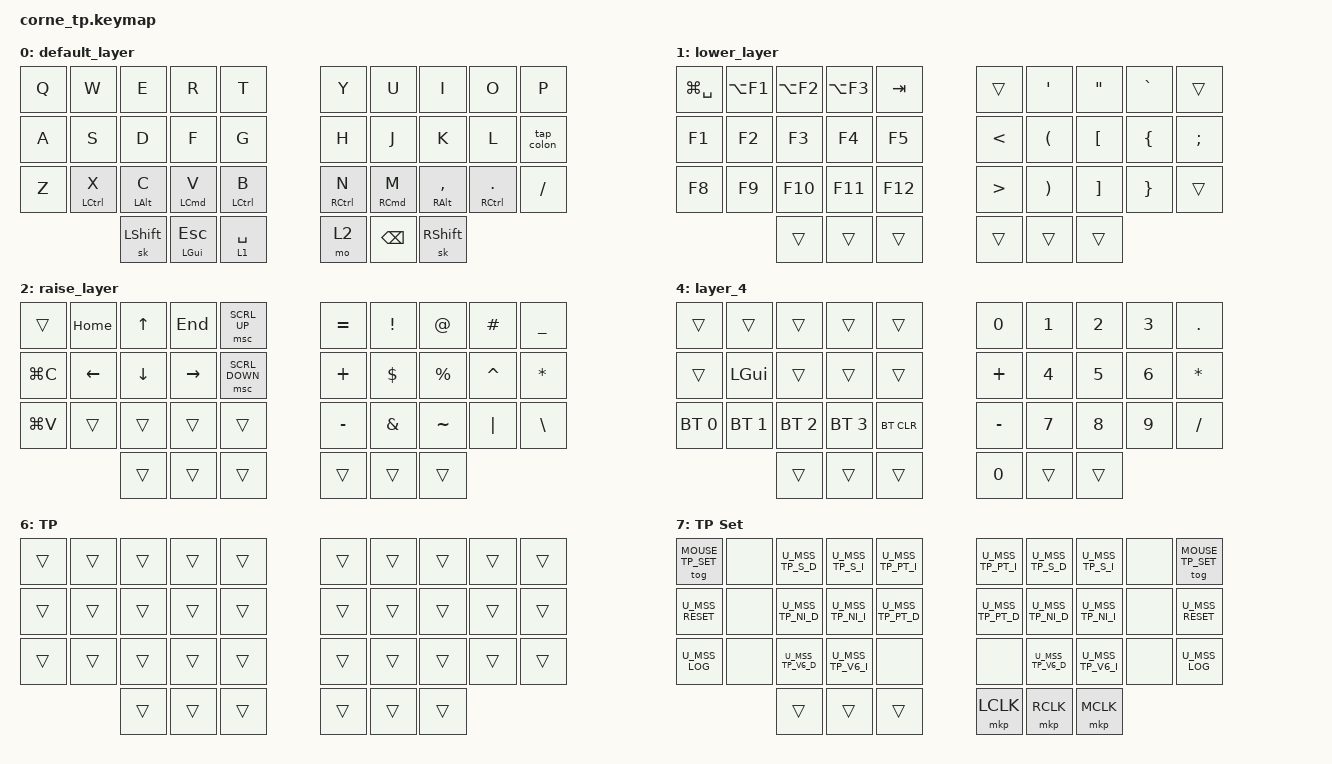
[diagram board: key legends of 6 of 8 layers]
/*
* Copyright (c) 2020 The ZMK Contributors
*
* SPDX-License-Identifier: MIT
*/

#include "zmk-helpers/helper.h"

#define ZMK_MOUSE_DEFAULT_SCRL_VAL 80

#define HM_TAPPING_TERM 300
#define HM_TAPPING_TERM_FAST 200
#define HM_PRIOR_IDLE 100

#include "zmk-helpers/key-labels/36.h"                                      // key-position labels
#include <behaviors.dtsi>
#include <dt-bindings/zmk/bt.h>
#include <dt-bindings/zmk/keys.h>

// BEGIN TRACKPOINT
#define BASE 0
#define LOWER 1
#define MOUSE_KEYS 5
#define MOUSE_TP 6
#define MOUSE_TP_SET 7

/*
 * Defines to enable/disable features
 *
 * These defines allow us to conditionally enable and disable parts of the keymap config.
 *
 * For example, if we decide to build the firmware without the mouse features, we can
 * disable all the config options that rely on those forks and modules without having
 * to edit the entire keymap file manually every time.
 */

#define HAS_MOUSE_KEYS
#define HAS_MOUSE_TP

#ifdef HAS_MOUSE_KEYS
  #include <dt-bindings/zmk/mouse.h>
  #include <behaviors/mouse_keys.dtsi>
#endif  // HAS_MOUSE_KEYS

#ifdef HAS_MOUSE_TP
  // We store the trackpoint settings in a separate file
  // to make organization a little easier.
  #include "include/mouse_tp.dtsi"
#endif  // HAS_MOUSE_TP



// Adjust layer keys based on enabled features.
//
// This prevents build errors when we build the firmware
// without the mouse keys PR or the TP module.
#ifdef HAS_MOUSE_KEYS
  #define U_THUMB_INNER &mo MOUSE_KEYS
#else
  #define U_THUMB_INNER &none
#endif  // HAS_MOUSE_KEYS

#ifdef HAS_MOUSE_TP
  #define U_TOG_TP_SET &tog MOUSE_TP_SET
#else
  #define U_TOG_TP_SET &none
#endif  // HAS_MOUSE_TP

// END TRACKPOINT

#define KEYS_L LT0 LT1 LT2 LT3 LT4 LM0 LM1 LM2 LM3 LM4 LB0 LB1 LB2 LB3 LB4  // left-hand keys
#define KEYS_R RT0 RT1 RT2 RT3 RT4 RM0 RM1 RM2 RM3 RM4 RB0 RB1 RB2 RB3 RB4  // right-hand keys
#define THUMBS LH2 LH1 LH0 RH0 RH1 RH2                                      // thumb keys

&lt {
    // Increase layer tap time

    tapping-term-ms = <200>;

    // Quickly tap-tap-holding the lt button will repeat the tap behavior
    // For example enter-enter-hold, will output multiple enter while you
    // keep holding the key.
    // But holding enter without double tapping, will activate the layer.

    quick-tap-ms = <150>;
    flavor = "tap-unless-interrupted";
};

/ {
    behaviors {
        // Positional Homerow mods
        // Homerow mods that prevent accidental activations when rolling keys,
        // such as when typing `st` or `ne` on colemak-dh layouts or `as` on
        // qwerty.
        //
        // Works by only allowing a mod to activate within tapping-term if
        // it's on the opposite side of the keyboard or on the same side thumb
        // keys.
        // Further optimization using urob's timerless homerow mods method:
        // https://github.com/urob/zmk-config#timeless-homerow-mods

        hml: homerow_mods_left {
            compatible = "zmk,behavior-hold-tap";
            #binding-cells = <2>;
            bindings = <&kp>, <&kp>;

            flavor = "balanced";
            tapping-term-ms = <HM_TAPPING_TERM>;
            quick-tap-ms = <175>;                // repeat on tap-into-hold
            require-prior-idle-ms = <HM_PRIOR_IDLE>;
            hold-trigger-key-positions = <KEYS_R THUMBS>;
            hold-trigger-on-release;
        };

        hmr: homerow_mods_right {
            compatible = "zmk,behavior-hold-tap";
            #binding-cells = <2>;
            bindings = <&kp>, <&kp>;

            flavor = "balanced";
            tapping-term-ms = <HM_TAPPING_TERM>;
            quick-tap-ms = <175>;
            require-prior-idle-ms = <HM_PRIOR_IDLE>;
            hold-trigger-key-positions = <KEYS_L THUMBS>;
            hold-trigger-on-release;
        };

        // Positional Homerow mods for shift
        // Use faster tapping term and disable some features that may
        // cause false negatives.

        //hmsl: hm_shift_l {
        //    compatible = "zmk,behavior-hold-tap";
        //    #binding-cells = <2>;
        //    bindings = <&kp>, <&kp>;

        //    flavor = "balanced";
        //    tapping-term-ms = <HM_TAPPING_TERM_FAST>;
        //    quick-tap-ms = <175>;
        //    require-prior-idle-ms = <HM_PRIOR_IDLE>;
        //    hold-trigger-key-positions = <KEYS_R THUMBS>;

        //    // hold-trigger-on-release;
        //};

        //hmsr: hm_shift_r {
        //    compatible = "zmk,behavior-hold-tap";
        //    #binding-cells = <2>;
        //    bindings = <&kp>, <&kp>;

        //    flavor = "balanced";
        //    tapping-term-ms = <HM_TAPPING_TERM_FAST>;
        //    quick-tap-ms = <175>;
        //    require-prior-idle-ms = <HM_PRIOR_IDLE>;
        //    hold-trigger-key-positions = <KEYS_L THUMBS>;

        //    // hold-trigger-on-release;
        //};

        /*
         * Non-Positional Homerow Mods
         * Used for &mm_grescm_gui behavior on left hand.
         *
         * Usage: &hm LSHFT T
         * Tap: T
         * Tap-Tap-Hold: Repeat T
         * Hold: LSHIFT
         */

        hm: homerow_mods {
            compatible = "zmk,behavior-hold-tap";
            #binding-cells = <2>;
            bindings = <&kp>, <&kp>;

            flavor = "balanced";
            tapping-term-ms = <HM_TAPPING_TERM>;
            quick-tap-ms = <200>;
        };

        rot_msc: sensor_rotate_msc {
            compatible = "zmk,behavior-sensor-rotate-var";
            #sensor-binding-cells = <2>;
            bindings = <&msc>, <&msc>;
            tap-ms = <20>;

        };

        rot_kp: sensor_rotate_kp {
            compatible = "zmk,behavior-sensor-rotate-var";
            #sensor-binding-cells = <2>;
            bindings = <&kp>, <&kp>;
        };
    };
};

/ {
    macros {
        //moom_full: moom_full {
        //    compatible = "zmk,behavior-macro";
        //    #binding-cells = <0>;
        //    bindings = <&kp LC(LA(LG(SPACE))) &kp SPACE>;
        //    label = "MOOM_FULL";
        //};

        //moom_left: moom_left {
        //    compatible = "zmk,behavior-macro";
        //    #binding-cells = <0>;
        //    bindings = <&kp LA(LC(LG(SPACE))) &kp LG(LEFT)>;
        //    label = "MOOM_LEFT";
        //};

        //moom_right: moom_right {
        //    compatible = "zmk,behavior-macro";
        //    #binding-cells = <0>;
        //    bindings = <&kp LA(LC(LG(SPACE))) &kp LG(RIGHT_ARROW)>;
        //    label = "MOOM_RIGHT";
        //};

        save_vim: save_vim {
            compatible = "zmk,behavior-macro";
            #binding-cells = <0>;
            bindings = <&kp ESCAPE &kp ESCAPE &kp SPACE &kp SPACE>;
            label = "SAVE_VIM";
        };

        tap_colon: super_colon {
            compatible = "zmk,behavior-macro";
            #binding-cells = <0>;
            bindings = <&kp COLON>;
            label = "SUPER_COLON";
        };
    };

    combos {
        compatible = "zmk,combos";
        timeout-ms = <30>;

        numlayer {
            bindings = <&sl 4>;
            key-positions = <LM1 LM2>;
        };

        homerow_hyperspace {
            bindings = <&kp LS(LA(LC(LG(SPACE))))>;
            key-positions = <LH1 RH1>;
        };

        //cmd_space {
        //    bindings = <&kp LG(SPACE)>;
        //    key-positions = <LM0 RM0>;
        //};

        return {
            bindings = <&kp RETURN>;
            key-positions = <RM2 RM3>;
        };

        hyper {
            bindings = <&sk LA(LC(LG(LEFT_SHIFT)))>;
            key-positions = <LH2 RH2>;
        };

        left_click {
            bindings = <&mkp LCLK>;
            key-positions = <RH0 RH1>;
        };

        middle_click {
            bindings = <&mkp MCLK>;
            key-positions = <RH1 RB0>;
        };

        right_click {
            bindings = <&mkp RCLK>;
            key-positions = <RH1 RH2>;
        };

        control_b {
          bindings = <&kp LC(B)>;
          key-positions = <LM4 RM4>;
        };

        //less_than {
        //  bindings = <&kp LESS_THAN>;
        //  key-positions = <LT1 LT2 LT3>;
        //};

        //greater_than {
        //  bindings = <&kp GREATER_THAN>;
        //  key-positions = <RT1 RT2 RT3>;
        //};

        caps_word_combo {
          bindings = <&caps_word>;
          key-positions = <LB3 LB2>;
        };
    };

    behaviors {
        //thumb_0: thumb_0 {
        //    compatible = "zmk,behavior-tap-dance";
        //    label = "THUMB_0";
        //    #binding-cells = <0>;
        //    bindings = <&sk LEFT_SHIFT>, <&caps_word>;
        //};

        //thumb_1: thumb_1 {
        //    compatible = "zmk,behavior-tap-dance";
        //    label = "THUMB_1";
        //    #binding-cells = <0>;
        //    bindings = <&sk RIGHT_SHIFT>, <&caps_word>;
        //};

        //paren: paren {
        //    compatible = "zmk,behavior-hold-tap";
        //    label = "PAREN";
        //    bindings = <&kp>, <&kp>;

        //    #binding-cells = <2>;
        //    tapping-term-ms = <150>;
        //    flavor = "tap-preferred";
        //};

        //alpha_ht: alpha_ht {
        //    compatible = "zmk,behavior-hold-tap";
        //    label = "ALPHA_HT";
        //    bindings = <&kp>, <&kp>;

        //    #binding-cells = <2>;
        //    tapping-term-ms = <150>;
        //    flavor = "tap-preferred";
        //};
    };

    keymap {
        compatible = "zmk,keymap";

        default_layer {
            bindings = <
&kp Q  &kp W                &kp E            &kp R                 &kp T                  &kp Y                 &kp U                 &kp I                 &kp O                   &kp P
&kp A  &kp S                &kp D            &kp F                 &kp G                  &kp H                 &kp J                 &kp K                 &kp L                   &tap_colon
&kp Z  &hml LEFT_CONTROL X  &hml LEFT_ALT C  &hml LEFT_COMMAND V   &hml LEFT_CONTROL B    &hmr RIGHT_CONTROL N  &hmr RIGHT_COMMAND M  &hmr RIGHT_ALT COMMA  &hmr RIGHT_CONTROL DOT  &kp SLASH 
                      &sk LEFT_SHIFT         &hmr LEFT_GUI ESCAPE  &lt 1 SPACE            &mo 2                 &kp BACKSPACE         &sk RIGHT_SHIFT
            >;
            sensor-bindings = <&rot_msc SCRL_UP SCRL_DOWN &inc_dec_kp LEFT RIGHT>;
        };

        lower_layer {
            bindings = <
&kp LG(SPACE)  &kp LA(F1)  &kp LA(F2)  &kp LA(F3)  &kp TAB                  &trans             &kp SINGLE_QUOTE       &kp DOUBLE_QUOTES   &kp GRAVE       &trans
&kp F1         &kp F2      &kp F3      &kp F4      &kp F5                   &kp LESS_THAN      &kp LEFT_PARENTHESIS   &kp LEFT_BRACKET   &kp LEFT_BRACE   &kp SEMICOLON
&kp F8         &kp F9      &kp F10     &kp F11     &kp F12                  &kp GREATER_THAN   &kp RIGHT_PARENTHESIS  &kp RIGHT_BRACKET  &kp RIGHT_BRACE  &trans
                           &trans      &trans      &trans                   &trans             &trans                 &trans
            >;
        };

        raise_layer {
            bindings = <
&trans      &kp HOME  &kp UP                 &kp END    &msc SCRL_UP       &kp EQUAL  &kp EXCL       &kp AT       &kp HASH   &kp UNDER
&kp LG(C)   &kp LEFT  &kp DOWN               &kp RIGHT  &msc SCRL_DOWN     &kp PLUS   &kp DOLLAR     &kp PERCENT  &kp CARET  &kp STAR
&kp LG(V)   &trans    &trans                 &trans     &trans             &kp MINUS  &kp AMPERSAND  &kp TILDE    &kp PIPE   &kp BACKSLASH
                      &trans                 &trans     &trans             &trans     &trans         &trans
            >;
        };

        layer_3 {
            bindings = <
&kp C_BRIGHTNESS_INC  &kp LC(LS(LG(N4)))  &kp LC(K)     &trans            &kp LA(TAB)        &kp LS(TAB)    &kp LA(LC(LG(LEFT)))  &kp LA(LC(LG(SPACE)))  &kp LA(LC(LG(RIGHT)))  &kp C_VOLUME_UP
&kp C_BRIGHTNESS_DEC  &kp LC(H)           &kp LC(J)     &kp LC(L)         &trans             &kp LG(EQUAL)  &trans                &save_vim              &trans                 &kp C_VOLUME_DOWN
&trans                &trans              &trans        &trans            &trans             &kp LG(MINUS)  &trans                &trans                 &trans                 &trans
                                          &trans        &trans            &trans             &trans         &trans                &trans
            >;
        };

        layer_4 {
            bindings = <
&trans        &trans        &trans        &trans        &trans        &kp N0     &kp N1  &kp N2  &kp N3  &kp PERIOD
&trans        &kp LEFT_GUI  &trans        &trans        &trans        &kp PLUS   &kp N4  &kp N5  &kp N6  &kp STAR
&bt BT_SEL 0  &bt BT_SEL 1  &bt BT_SEL 2  &bt BT_SEL 3  &bt BT_CLR    &kp MINUS  &kp N7  &kp N8  &kp N9  &kp SLASH
                                    &trans        &trans        &trans        &kp N0     &trans  &trans
            >;
        };

// TRACKPOINT
#ifdef HAS_MOUSE_KEYS

        MouseKeys_layer {
          display-name = "MouseKeys";
          bindings = <
U_TOG_TP_SET             &none                    &mmv MOVE_UP             &msc SCRL_UP
&none                    &mmv MOVE_LEFT           &mmv MOVE_DOWN           &mmv MOVE_RIGHT
&none                    &none                    &none                    &msc SCRL_DOWN
                                                                                   &trans                   &trans                   &trans                        &mkp LCLK                &trans                   &mkp RCLK
          >;
        };

#endif

#ifdef HAS_MOUSE_TP

        // Automatically activated when the mouse or trackpoint moves.
        // Configured in `include/mouse_tp.dtsi`.
        MouseTP_layer {
          display-name = "TP";
          bindings = <
&trans                   &trans                   &trans                   &trans                   &trans                        &trans                   &trans                   &trans                   &trans                   &trans
&trans                   &trans                   &trans                   &trans                   &trans                        &trans                   &trans                   &trans                   &trans                   &trans
&trans                   &trans                   &trans                   &trans                   &trans                        &trans                   &trans                   &trans                   &trans                   &trans
                                                                                   &trans                   &trans                   &trans                        &trans                   &trans                   &trans
          >;
        };

        // You can find the defines for the actual key press behaviors in `include/mouse_tp.dtsi`.
        MouseSettings_layer {
          display-name = "TP Set";
          bindings = <
U_TOG_TP_SET             &none                    U_MSS_TP_S_D             U_MSS_TP_S_I             U_MSS_TP_PT_I                 U_MSS_TP_PT_I            U_MSS_TP_S_D             U_MSS_TP_S_I             &none                    U_TOG_TP_SET
U_MSS_RESET              &none                    U_MSS_TP_NI_D            U_MSS_TP_NI_I            U_MSS_TP_PT_D                 U_MSS_TP_PT_D            U_MSS_TP_NI_D            U_MSS_TP_NI_I            &none                    U_MSS_RESET
U_MSS_LOG                &none                    U_MSS_TP_V6_D            U_MSS_TP_V6_I            &none                         &none                    U_MSS_TP_V6_D            U_MSS_TP_V6_I            &none                    U_MSS_LOG
                                                                                    &trans                  &trans                   &trans                        &mkp LCLK                &mkp RCLK                &mkp MCLK
          >;
        };

#endif
    };

    conditional_layers {
        compatible = "zmk,conditional-layers";

        tri-layer {
            if-layers = <1 2>;
            then-layer = <3>;
        };
    };
};
